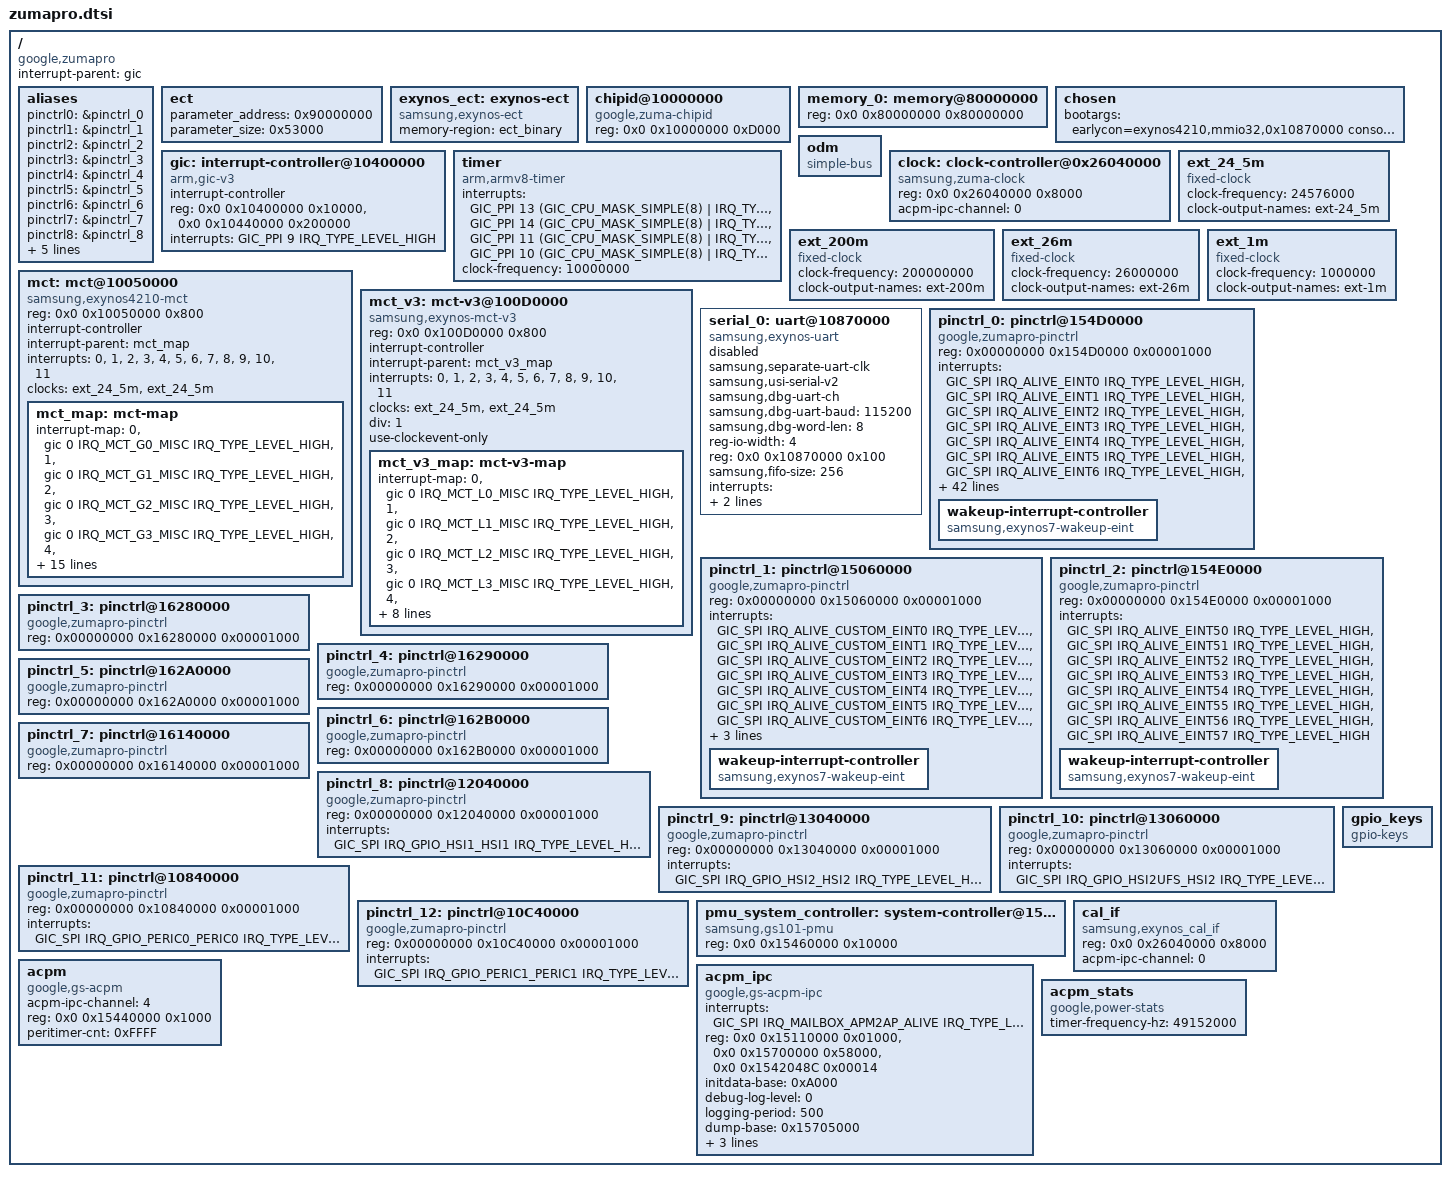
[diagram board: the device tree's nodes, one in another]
// SPDX-License-Identifier: GPL-2.0-only
/*
 * Copyright 2023 Google LLC.
 *
 */

#include <dt-bindings/gpio/gpio.h>
#include <dt-bindings/interrupt-controller/arm-gic.h>
#include <dt-bindings/interrupt-controller/zumapro.h>
#include <dt-bindings/clock/zuma.h>
#include "zumapro-drm-dpu.dtsi"
#include "zumapro-sysmmu.dtsi"
#include "zumapro-dma-heap.dtsi"
#include "zumapro-rmem.dtsi"
#include "gs101-trusty.dtsi"
#include "zumapro-pm-domains.dtsi"
#include "zumapro-cpu.dtsi"
#include "zumapro-pinctrl.dtsi"
#include "zumapro-usi.dtsi"
#include "zumapro-usb.dtsi"
#include "gs101-dma-heap.dtsi"
#include "gs101-faceauth-dma-heap.dtsi"

/ {
	compatible = "google,zumapro";
	interrupt-parent = <&gic>;
	#address-cells = <2>;
	#size-cells = <1>;

	aliases {
		pinctrl0 = &pinctrl_0;
		pinctrl1 = &pinctrl_1;
		pinctrl2 = &pinctrl_2;
		pinctrl3 = &pinctrl_3;
		pinctrl4 = &pinctrl_4;
		pinctrl5 = &pinctrl_5;
		pinctrl6 = &pinctrl_6;
		pinctrl7 = &pinctrl_7;
		pinctrl8 = &pinctrl_8;
		pinctrl9 = &pinctrl_9;
		pinctrl10 = &pinctrl_10;
		pinctrl11 = &pinctrl_11;
		pinctrl12 = &pinctrl_12;
		uart0 = &serial_0;
	};

	ect {
		parameter_address = <0x90000000>;
		parameter_size = <0x53000>;
	};

	exynos_ect: exynos-ect {
		compatible = "samsung,exynos-ect";
		memory-region = <&ect_binary>;
	};

	chipid@10000000 {
		compatible = "google,zuma-chipid";
		reg = <0x0 0x10000000 0xD000>;
	};

	memory_0: memory@80000000 {
		device_type = "memory";
		reg = <0x0 0x80000000 0x80000000>;
	};

	chosen: chosen {
		bootargs = "earlycon=exynos4210,mmio32,0x10870000 console=ttySAC0,115200n8 root=/dev/ram0 rw clocksource=arch_sys_counter androidboot.hardware=zuma androidboot.hardware.platform=zuma androidboot.debug_level=0x4948 clk_ignore_unused loop.max_part=7 loop.hw_queue_depth=31 coherent_pool=4M firmware_class.path=/vendor/firmware irqaffinity=0 swiotlb=noforce androidboot.slot_suffix=_a androidboot.secure_boot=NONE sysrq_always_enabled no_console_suspend softlockup_panic=1 kasan_multi_shot kvm-arm.protected_modules=exynos-pd,pkvm_s2mpu-v9 maxcpus=1 androidboot.first_stage_console=1 androidboot.force_normal_boot=1";
	};

	odm: odm {
		compatible = "simple-bus";
		ranges;

		/* reserved for overlay by ODM */
	};

	gic: interrupt-controller@10400000 {
		compatible = "arm,gic-v3";
		#interrupt-cells = <3>;
		interrupt-controller;
		reg = <0x0 0x10400000 0x10000>,		/* GICD */
		      <0x0 0x10440000 0x200000>;	/* GICR * 8 */
		interrupts = <GIC_PPI 9 IRQ_TYPE_LEVEL_HIGH>;
	};

	timer {
		compatible = "arm,armv8-timer";
		interrupts = <GIC_PPI 13 (GIC_CPU_MASK_SIMPLE(8) | IRQ_TYPE_LEVEL_LOW)>,
			     <GIC_PPI 14 (GIC_CPU_MASK_SIMPLE(8) | IRQ_TYPE_LEVEL_LOW)>,
			     <GIC_PPI 11 (GIC_CPU_MASK_SIMPLE(8) | IRQ_TYPE_LEVEL_LOW)>,
			     <GIC_PPI 10 (GIC_CPU_MASK_SIMPLE(8) | IRQ_TYPE_LEVEL_LOW)>;
		clock-frequency = <10000000>;
	};

	clock: clock-controller@0x26040000 {
		compatible = "samsung,zuma-clock";
		reg = <0x0 0x26040000 0x8000>;
		#clock-cells = <1>;
		acpm-ipc-channel = <0>;
	};

	ext_24_5m: ext_24_5m {
		compatible = "fixed-clock";
		#clock-cells = <0>;
		clock-frequency = <24576000>;
		clock-output-names = "ext-24_5m";
	};

	ext_200m: ext_200m {
		compatible = "fixed-clock";
		#clock-cells = <0>;
		clock-frequency = <200000000>;
		clock-output-names = "ext-200m";
	};

	ext_26m: ext_26m {
		compatible = "fixed-clock";
		#clock-cells = <0>;
		clock-frequency = <26000000>;
		clock-output-names = "ext-26m";
	};

	ext_1m: ext_1m {
		compatible = "fixed-clock";
		#clock-cells = <0>;
		clock-frequency = <1000000>;
		clock-output-names = "ext-1m";
	};

	mct: mct@10050000 {
		compatible = "samsung,exynos4210-mct";
		reg = <0x0 0x10050000 0x800>;
		interrupt-controller;
		#interrupt-cells = <1>;
		interrupt-parent = <&mct_map>;
		interrupts = <0>, <1>, <2>, <3>,
			     <4>, <5>, <6>, <7>,
			     <8>, <9>, <10>, <11>;
		clocks = <&ext_24_5m>, <&ext_24_5m>;
		clock-names = "fin_pll", "mct";

		mct_map: mct-map {
			#interrupt-cells = <1>;
			#address-cells = <0>;
			#size-cells = <0>;
			interrupt-map = <0 &gic 0 IRQ_MCT_G0_MISC IRQ_TYPE_LEVEL_HIGH>,
					<1 &gic 0 IRQ_MCT_G1_MISC IRQ_TYPE_LEVEL_HIGH>,
					<2 &gic 0 IRQ_MCT_G2_MISC IRQ_TYPE_LEVEL_HIGH>,
					<3 &gic 0 IRQ_MCT_G3_MISC IRQ_TYPE_LEVEL_HIGH>,
					<4 &gic 0 IRQ_MCT_L0_MISC IRQ_TYPE_LEVEL_HIGH>,
					<5 &gic 0 IRQ_MCT_L1_MISC IRQ_TYPE_LEVEL_HIGH>,
					<6 &gic 0 IRQ_MCT_L2_MISC IRQ_TYPE_LEVEL_HIGH>,
					<7 &gic 0 IRQ_MCT_L3_MISC IRQ_TYPE_LEVEL_HIGH>,
					<8 &gic 0 IRQ_MCT_L4_MISC IRQ_TYPE_LEVEL_HIGH>,
					<9 &gic 0 IRQ_MCT_L5_MISC IRQ_TYPE_LEVEL_HIGH>,
					<10 &gic 0 IRQ_MCT_L6_MISC IRQ_TYPE_LEVEL_HIGH>,
					<11 &gic 0 IRQ_MCT_L7_MISC IRQ_TYPE_LEVEL_HIGH>;
		};
	};

	mct_v3: mct-v3@100D0000 {
		compatible = "samsung,exynos-mct-v3";
		reg = <0x0 0x100D0000 0x800>;
		interrupt-controller;
		#interrupt-cells = <1>;
		interrupt-parent = <&mct_v3_map>;
		interrupts =    <0>, <1>, <2>, <3>,
				<4>, <5>, <6>, <7>,
				<8>, <9>, <10>, <11>;
		clocks = <&ext_24_5m>, <&ext_24_5m>;
		clock-names = "fin_pll", "mct";
		div = <1>;
		use-clockevent-only;

		mct_v3_map: mct-v3-map {
			#interrupt-cells = <1>;
			#address-cells = <0>;
			#size-cells = <0>;

			interrupt-map = <0 &gic 0 IRQ_MCT_L0_MISC IRQ_TYPE_LEVEL_HIGH>,
					<1 &gic 0 IRQ_MCT_L1_MISC IRQ_TYPE_LEVEL_HIGH>,
					<2 &gic 0 IRQ_MCT_L2_MISC IRQ_TYPE_LEVEL_HIGH>,
					<3 &gic 0 IRQ_MCT_L3_MISC IRQ_TYPE_LEVEL_HIGH>,
					<4 &gic 0 IRQ_MCT_L4_MISC IRQ_TYPE_LEVEL_HIGH>,
					<5 &gic 0 IRQ_MCT_L5_MISC IRQ_TYPE_LEVEL_HIGH>,
					<6 &gic 0 IRQ_MCT_L6_MISC IRQ_TYPE_LEVEL_HIGH>,
					<7 &gic 0 IRQ_MCT_L7_MISC IRQ_TYPE_LEVEL_HIGH>,
					<8 &gic 0 IRQ_MCT_L8_MISC IRQ_TYPE_LEVEL_HIGH>;

		};
	};

	serial_0: uart@10870000 {
		compatible = "samsung,exynos-uart";
		samsung,separate-uart-clk;
		samsung,usi-serial-v2;
		samsung,dbg-uart-ch;
		samsung,dbg-uart-baud = <115200>;
		samsung,dbg-word-len = <8>;
		reg-io-width = <4>;
		reg = <0x0 0x10870000 0x100>;
		samsung,fifo-size = <256>;
		interrupts = <GIC_SPI IRQ_USI0_UART_PERIC0 IRQ_TYPE_LEVEL_HIGH>;
		clocks = <&ext_200m>, <&ext_200m>;
		clock-names = "gate_uart_clk0", "ipclk_uart0";
		status = "disabled";
	};

	/* GPIO_ALIVE */
	pinctrl_0: pinctrl@154D0000 {
		compatible = "google,zumapro-pinctrl";
		reg = <0x00000000 0x154D0000 0x00001000>;
		interrupts = <GIC_SPI IRQ_ALIVE_EINT0 IRQ_TYPE_LEVEL_HIGH>,
		     <GIC_SPI IRQ_ALIVE_EINT1 IRQ_TYPE_LEVEL_HIGH>,
		     <GIC_SPI IRQ_ALIVE_EINT2 IRQ_TYPE_LEVEL_HIGH>,
		     <GIC_SPI IRQ_ALIVE_EINT3 IRQ_TYPE_LEVEL_HIGH>,
		     <GIC_SPI IRQ_ALIVE_EINT4 IRQ_TYPE_LEVEL_HIGH>,
		     <GIC_SPI IRQ_ALIVE_EINT5 IRQ_TYPE_LEVEL_HIGH>,
		     <GIC_SPI IRQ_ALIVE_EINT6 IRQ_TYPE_LEVEL_HIGH>,
		     <GIC_SPI IRQ_ALIVE_EINT7 IRQ_TYPE_LEVEL_HIGH>,
		     <GIC_SPI IRQ_ALIVE_EINT8 IRQ_TYPE_LEVEL_HIGH>,
		     <GIC_SPI IRQ_ALIVE_EINT9 IRQ_TYPE_LEVEL_HIGH>,
		     <GIC_SPI IRQ_ALIVE_EINT10 IRQ_TYPE_LEVEL_HIGH>,
		     <GIC_SPI IRQ_ALIVE_EINT11 IRQ_TYPE_LEVEL_HIGH>,
		     <GIC_SPI IRQ_ALIVE_EINT12 IRQ_TYPE_LEVEL_HIGH>,
		     <GIC_SPI IRQ_ALIVE_EINT13 IRQ_TYPE_LEVEL_HIGH>,
		     <GIC_SPI IRQ_ALIVE_EINT14 IRQ_TYPE_LEVEL_HIGH>,
		     <GIC_SPI IRQ_ALIVE_EINT15 IRQ_TYPE_LEVEL_HIGH>,
		     <GIC_SPI IRQ_ALIVE_EINT16 IRQ_TYPE_LEVEL_HIGH>,
		     <GIC_SPI IRQ_ALIVE_EINT17 IRQ_TYPE_LEVEL_HIGH>,
		     <GIC_SPI IRQ_ALIVE_EINT18 IRQ_TYPE_LEVEL_HIGH>,
		     <GIC_SPI IRQ_ALIVE_EINT20 IRQ_TYPE_LEVEL_HIGH>,
		     <GIC_SPI IRQ_ALIVE_EINT21 IRQ_TYPE_LEVEL_HIGH>,
		     <GIC_SPI IRQ_ALIVE_EINT22 IRQ_TYPE_LEVEL_HIGH>,
		     <GIC_SPI IRQ_ALIVE_EINT23 IRQ_TYPE_LEVEL_HIGH>,
		     <GIC_SPI IRQ_ALIVE_EINT24 IRQ_TYPE_LEVEL_HIGH>,
		     <GIC_SPI IRQ_ALIVE_EINT25 IRQ_TYPE_LEVEL_HIGH>,
		     <GIC_SPI IRQ_ALIVE_EINT26 IRQ_TYPE_LEVEL_HIGH>,
		     <GIC_SPI IRQ_ALIVE_EINT27 IRQ_TYPE_LEVEL_HIGH>,
		     <GIC_SPI IRQ_ALIVE_EINT28 IRQ_TYPE_LEVEL_HIGH>,
		     <GIC_SPI IRQ_ALIVE_EINT29 IRQ_TYPE_LEVEL_HIGH>,
		     <GIC_SPI IRQ_ALIVE_EINT30 IRQ_TYPE_LEVEL_HIGH>,
		     <GIC_SPI IRQ_ALIVE_EINT31 IRQ_TYPE_LEVEL_HIGH>,
		     <GIC_SPI IRQ_ALIVE_EINT32 IRQ_TYPE_LEVEL_HIGH>,
		     <GIC_SPI IRQ_ALIVE_EINT33 IRQ_TYPE_LEVEL_HIGH>,
		     <GIC_SPI IRQ_ALIVE_EINT34 IRQ_TYPE_LEVEL_HIGH>,
		     <GIC_SPI IRQ_ALIVE_EINT35 IRQ_TYPE_LEVEL_HIGH>,
		     <GIC_SPI IRQ_ALIVE_EINT36 IRQ_TYPE_LEVEL_HIGH>,
		     <GIC_SPI IRQ_ALIVE_EINT37 IRQ_TYPE_LEVEL_HIGH>,
		     <GIC_SPI IRQ_ALIVE_EINT38 IRQ_TYPE_LEVEL_HIGH>,
		     <GIC_SPI IRQ_ALIVE_EINT39 IRQ_TYPE_LEVEL_HIGH>,
		     <GIC_SPI IRQ_ALIVE_EINT40 IRQ_TYPE_LEVEL_HIGH>,
		     <GIC_SPI IRQ_ALIVE_EINT41 IRQ_TYPE_LEVEL_HIGH>,
		     <GIC_SPI IRQ_ALIVE_EINT42 IRQ_TYPE_LEVEL_HIGH>,
		     <GIC_SPI IRQ_ALIVE_EINT43 IRQ_TYPE_LEVEL_HIGH>,
		     <GIC_SPI IRQ_ALIVE_EINT44 IRQ_TYPE_LEVEL_HIGH>,
		     <GIC_SPI IRQ_ALIVE_EINT45 IRQ_TYPE_LEVEL_HIGH>,
		     <GIC_SPI IRQ_ALIVE_EINT46 IRQ_TYPE_LEVEL_HIGH>,
		     <GIC_SPI IRQ_ALIVE_EINT47 IRQ_TYPE_LEVEL_HIGH>,
		     <GIC_SPI IRQ_ALIVE_EINT48 IRQ_TYPE_LEVEL_HIGH>,
		     <GIC_SPI IRQ_ALIVE_EINT49 IRQ_TYPE_LEVEL_HIGH>;
		wakeup-interrupt-controller {
			compatible = "samsung,exynos7-wakeup-eint";
		};
	};

	/* GPIO_CUSTOM_ALIVE */
	pinctrl_1: pinctrl@15060000 {
		compatible = "google,zumapro-pinctrl";
		reg = <0x00000000 0x15060000 0x00001000>;
		interrupts = <GIC_SPI IRQ_ALIVE_CUSTOM_EINT0 IRQ_TYPE_LEVEL_HIGH>,
			     <GIC_SPI IRQ_ALIVE_CUSTOM_EINT1 IRQ_TYPE_LEVEL_HIGH>,
			     <GIC_SPI IRQ_ALIVE_CUSTOM_EINT2 IRQ_TYPE_LEVEL_HIGH>,
			     <GIC_SPI IRQ_ALIVE_CUSTOM_EINT3 IRQ_TYPE_LEVEL_HIGH>,
			     <GIC_SPI IRQ_ALIVE_CUSTOM_EINT4 IRQ_TYPE_LEVEL_HIGH>,
			     <GIC_SPI IRQ_ALIVE_CUSTOM_EINT5 IRQ_TYPE_LEVEL_HIGH>,
			     <GIC_SPI IRQ_ALIVE_CUSTOM_EINT6 IRQ_TYPE_LEVEL_HIGH>,
			     <GIC_SPI IRQ_ALIVE_CUSTOM_EINT7 IRQ_TYPE_LEVEL_HIGH>,
			     <GIC_SPI IRQ_ALIVE_CUSTOM_EINT8 IRQ_TYPE_LEVEL_HIGH>,
			     <GIC_SPI IRQ_ALIVE_CUSTOM_EINT9 IRQ_TYPE_LEVEL_HIGH>;

			wakeup-interrupt-controller {
				compatible = "samsung,exynos7-wakeup-eint";
			};
	};

	/* GPIO_FAR_ALIVE */
	pinctrl_2: pinctrl@154E0000 {
		compatible = "google,zumapro-pinctrl";
		reg = <0x00000000 0x154E0000 0x00001000>;
		interrupts = <GIC_SPI IRQ_ALIVE_EINT50 IRQ_TYPE_LEVEL_HIGH>,
			     <GIC_SPI IRQ_ALIVE_EINT51 IRQ_TYPE_LEVEL_HIGH>,
			     <GIC_SPI IRQ_ALIVE_EINT52 IRQ_TYPE_LEVEL_HIGH>,
			     <GIC_SPI IRQ_ALIVE_EINT53 IRQ_TYPE_LEVEL_HIGH>,
			     <GIC_SPI IRQ_ALIVE_EINT54 IRQ_TYPE_LEVEL_HIGH>,
			     <GIC_SPI IRQ_ALIVE_EINT55 IRQ_TYPE_LEVEL_HIGH>,
			     <GIC_SPI IRQ_ALIVE_EINT56 IRQ_TYPE_LEVEL_HIGH>,
			     <GIC_SPI IRQ_ALIVE_EINT57 IRQ_TYPE_LEVEL_HIGH>;

		wakeup-interrupt-controller {
			compatible = "samsung,exynos7-wakeup-eint";
		};
	};


	/* GPIO_GSACORE0 */
	pinctrl_3: pinctrl@16280000 {
		compatible = "google,zumapro-pinctrl";
		reg = <0x00000000 0x16280000 0x00001000>;
	};

	/* GPIO_GSACORE1 */
	pinctrl_4: pinctrl@16290000 {
		compatible = "google,zumapro-pinctrl";
		reg = <0x00000000 0x16290000 0x00001000>;
	};

	/* GPIO_GSACORE2 */
	pinctrl_5: pinctrl@162A0000 {
		compatible = "google,zumapro-pinctrl";
		reg = <0x00000000 0x162A0000 0x00001000>;
	};

	/* GPIO_GSACORE3 */
	pinctrl_6: pinctrl@162B0000 {
		compatible = "google,zumapro-pinctrl";
		reg = <0x00000000 0x162B0000 0x00001000>;
	};

	/* GPIO_GSACTRL */
	pinctrl_7: pinctrl@16140000 {
		compatible = "google,zumapro-pinctrl";
		reg = <0x00000000 0x16140000 0x00001000>;
	};

	/* GPIO_HSI1 */
	pinctrl_8: pinctrl@12040000 {
		compatible = "google,zumapro-pinctrl";
		reg = <0x00000000 0x12040000 0x00001000>;
		interrupts = <GIC_SPI IRQ_GPIO_HSI1_HSI1 IRQ_TYPE_LEVEL_HIGH>;
	};

	/* GPIO_HSI2 */
	pinctrl_9: pinctrl@13040000 {
		compatible = "google,zumapro-pinctrl";
		reg = <0x00000000 0x13040000 0x00001000>;
		interrupts = <GIC_SPI IRQ_GPIO_HSI2_HSI2 IRQ_TYPE_LEVEL_HIGH>;
	};

	/* GPIO_HSI2UFS */
	pinctrl_10: pinctrl@13060000 {
		compatible = "google,zumapro-pinctrl";
		reg = <0x00000000 0x13060000 0x00001000>;
		interrupts = <GIC_SPI IRQ_GPIO_HSI2UFS_HSI2 IRQ_TYPE_LEVEL_HIGH>;
	};

	/* GPIO_PERIC0 */
	pinctrl_11: pinctrl@10840000 {
		compatible = "google,zumapro-pinctrl";
		reg = <0x00000000 0x10840000 0x00001000>;
		interrupts = <GIC_SPI IRQ_GPIO_PERIC0_PERIC0 IRQ_TYPE_LEVEL_HIGH>;
	};

	/* GPIO_PERIC1 */
	pinctrl_12: pinctrl@10C40000 {
		compatible = "google,zumapro-pinctrl";
		reg = <0x00000000 0x10C40000 0x00001000>;
		interrupts = <GIC_SPI IRQ_GPIO_PERIC1_PERIC1 IRQ_TYPE_LEVEL_HIGH>;
	};

	pmu_system_controller: system-controller@15460000 {
		compatible = "samsung,gs101-pmu", "syscon";
		reg = <0x0 0x15460000 0x10000>;
	};

	gpio_keys: gpio_keys {
		compatible = "gpio-keys";
	};

	cal_if: cal_if {
		compatible = "samsung,exynos_cal_if";
		reg = <0x0 0x26040000 0x8000>;
		acpm-ipc-channel = <0>;
	};

	acpm {
		compatible = "google,gs-acpm";
		#address-cells = <2>;
		#size-cells = <1>;
		acpm-ipc-channel = <4>;
		reg = <0x0 0x15440000 0x1000>;  /* TIMER_APM */
		reg-names = "timer_apm";
		peritimer-cnt = <0xFFFF>;
	};

	acpm_ipc {
		compatible = "google,gs-acpm-ipc";
		#address-cells = <2>;
		#size-cells = <1>;
		interrupts = <GIC_SPI IRQ_MAILBOX_APM2AP_ALIVE IRQ_TYPE_LEVEL_HIGH>;
		reg = <0x0 0x15110000 0x01000>, /* AP2APM MAILBOX */
		      <0x0 0x15700000 0x58000>, /* APM SRAM region from AP view */
		      <0x0 0x1542048C 0x00014>; /* SYSREG_APM.ALIVE_FRC_CTRL0 */
		initdata-base = <0xA000>;
		debug-log-level = <0>;
		logging-period = <500>;
		dump-base = <0x15705000>;       /* Non-secure world base addr */
		dump-size = <0x53000>;          /* Non-secure SRAM size: 332KB(352-20) */
		acpm-ipc-channel = <12>;
		fvmap_addr = <0x31000>;
		/* panic-action = <GO_PANIC_ID>;*/
	};

	acpm_stats {
		compatible = "google,power-stats";
		timer-frequency-hz = <49152000>;
	};

};
